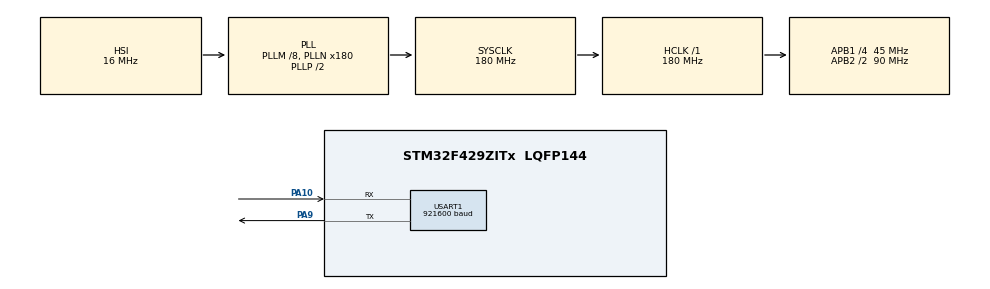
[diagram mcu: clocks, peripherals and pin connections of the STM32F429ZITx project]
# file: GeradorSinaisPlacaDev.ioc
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Mcu.Family=STM32F4
Mcu.Name=STM32F429ZITx
Mcu.Package=LQFP144
NVIC.PriorityGroup=NVIC_PRIORITYGROUP_4
NVIC.TIM7_IRQn=true\:0\:0\:false\:false\:true\:true\:true
NVIC.USART1_IRQn=true\:0\:0\:false\:false\:true\:true\:true
PA10.Mode=Asynchronous
PA10.Signal=USART1_RX
PA9.Mode=Asynchronous
PA9.Signal=USART1_TX
ProjectManager.HeapSize=0x200
ProjectManager.StackSize=0x400
ProjectManager.TargetToolchain=STM32CubeIDE
RCC.48MHZClocksFreq_Value=90000000
RCC.AHBFreq_Value=180000000
RCC.APB1CLKDivider=RCC_HCLK_DIV4
RCC.APB1Freq_Value=45000000
RCC.APB1TimFreq_Value=90000000
RCC.APB2CLKDivider=RCC_HCLK_DIV2
RCC.APB2Freq_Value=90000000
RCC.APB2TimFreq_Value=180000000
RCC.CortexFreq_Value=180000000
RCC.HCLKFreq_Value=180000000
RCC.HSE_VALUE=25000000
RCC.HSI_VALUE=16000000
RCC.LSE_VALUE=32768
RCC.PLLM=8
RCC.PLLN=180
RCC.SYSCLKFreq_VALUE=180000000
RCC.SYSCLKSource=RCC_SYSCLKSOURCE_PLLCLK
RCC.VCOOutputFreq_Value=360000000
TIM7.AutoReloadPreload=TIM_AUTORELOAD_PRELOAD_ENABLE
TIM7.Period=500
TIM7.Prescaler=90
TIM7.TIM_MasterOutputTrigger=TIM_TRGO_UPDATE
USART1.BaudRate=921600
USART1.VirtualMode=VM_ASYNC
VP_TIM7_VS_ClockSourceINT.Mode=Enable_Timer
board=custom

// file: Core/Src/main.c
/* USER CODE BEGIN Header */
/**
  ******************************************************************************
  * @file           : main.c
  * @brief          : Main program body
  ******************************************************************************
  * @attention
  *
  * <h2><center>&copy; Copyright (c) 2020 STMicroelectronics.
  * All rights reserved.</center></h2>
  *
  * This software component is licensed by ST under BSD 3-Clause license,
  * the "License"; You may not use this file except in compliance with the
  * License. You may obtain a copy of the License at:
  *                        opensource.org/licenses/BSD-3-Clause
  *
  ******************************************************************************
  */
/* USER CODE END Header */

#include "main.h"

/* USER CODE BEGIN Includes */

#include "Sinal.h"
#include <stdio.h>
/* USER CODE END Includes */

TIM_HandleTypeDef htim7;

UART_HandleTypeDef huart1;

/* USER CODE BEGIN PV */

volatile uint32_t TimeoutEnvioDados = 0;

/* USER CODE END PV */

void SystemClock_Config(void);
static void MX_GPIO_Init(void);
static void MX_USART1_UART_Init(void);
static void MX_TIM7_Init(void);

int main(void)
{

  /* MCU Configuration--------------------------------------------------------*/

  /* Reset of all peripherals, Initializes the Flash interface and the Systick. */
  HAL_Init();

  /* Configure the system clock */
  SystemClock_Config();

  /* Initialize all configured peripherals */
  MX_GPIO_Init();
  MX_USART1_UART_Init();
  MX_TIM7_Init();
  /* USER CODE BEGIN 2 */

  TimeoutEnvioDados = 1000;

  /* USER CODE END 2 */

  /* Infinite loop */
  while (1)
  {

    /* USER CODE BEGIN 3 */

	  if(TimeoutEnvioDados == 0){

//		  uint8_t pData[50] = " 0010 0020 0030\r";
//
//		  HAL_UART_Transmit_IT(&huart1, pData, 16);

		  TimeoutEnvioDados = 1;
	  }

  }
  /* USER CODE END 3 */
}

void SystemClock_Config(void)
{
  RCC_OscInitTypeDef RCC_OscInitStruct = {0};
  RCC_ClkInitTypeDef RCC_ClkInitStruct = {0};

  /** Configure the main internal regulator output voltage
  */
  __HAL_RCC_PWR_CLK_ENABLE();
  __HAL_PWR_VOLTAGESCALING_CONFIG(PWR_REGULATOR_VOLTAGE_SCALE1);
  /** Initializes the CPU, AHB and APB busses clocks
  */
  RCC_OscInitStruct.OscillatorType = RCC_OSCILLATORTYPE_HSI;
  RCC_OscInitStruct.HSIState = RCC_HSI_ON;
  RCC_OscInitStruct.HSICalibrationValue = RCC_HSICALIBRATION_DEFAULT;
  RCC_OscInitStruct.PLL.PLLState = RCC_PLL_ON;
  RCC_OscInitStruct.PLL.PLLSource = RCC_PLLSOURCE_HSI;
  RCC_OscInitStruct.PLL.PLLM = 8;
  RCC_OscInitStruct.PLL.PLLN = 180;
  RCC_OscInitStruct.PLL.PLLP = RCC_PLLP_DIV2;
  RCC_OscInitStruct.PLL.PLLQ = 4;
  if (HAL_RCC_OscConfig(&RCC_OscInitStruct) != HAL_OK)
  {
    Error_Handler();
  }
  /** Activate the Over-Drive mode
  */
  if (HAL_PWREx_EnableOverDrive() != HAL_OK)
  {
    Error_Handler();
  }
  /** Initializes the CPU, AHB and APB busses clocks
  */
  RCC_ClkInitStruct.ClockType = RCC_CLOCKTYPE_HCLK|RCC_CLOCKTYPE_SYSCLK
                              |RCC_CLOCKTYPE_PCLK1|RCC_CLOCKTYPE_PCLK2;
  RCC_ClkInitStruct.SYSCLKSource = RCC_SYSCLKSOURCE_PLLCLK;
  RCC_ClkInitStruct.AHBCLKDivider = RCC_SYSCLK_DIV1;
  RCC_ClkInitStruct.APB1CLKDivider = RCC_HCLK_DIV4;
  RCC_ClkInitStruct.APB2CLKDivider = RCC_HCLK_DIV2;

  if (HAL_RCC_ClockConfig(&RCC_ClkInitStruct, FLASH_LATENCY_5) != HAL_OK)
  {
    Error_Handler();
  }
}

static void MX_TIM7_Init(void)
{

  TIM_MasterConfigTypeDef sMasterConfig = {0};

  htim7.Instance = TIM7;
  htim7.Init.Prescaler = 90;
  htim7.Init.CounterMode = TIM_COUNTERMODE_UP;
  htim7.Init.Period = 500;
  htim7.Init.AutoReloadPreload = TIM_AUTORELOAD_PRELOAD_ENABLE;
  if (HAL_TIM_Base_Init(&htim7) != HAL_OK)
  {
    Error_Handler();
  }
  sMasterConfig.MasterOutputTrigger = TIM_TRGO_UPDATE;
  sMasterConfig.MasterSlaveMode = TIM_MASTERSLAVEMODE_DISABLE;
  if (HAL_TIMEx_MasterConfigSynchronization(&htim7, &sMasterConfig) != HAL_OK)
  {
    Error_Handler();
  }
  /* USER CODE BEGIN TIM7_Init 2 */

  __HAL_TIM_ENABLE(&htim7);
  __HAL_TIM_ENABLE_IT(&htim7,TIM_IT_UPDATE);

  /* USER CODE END TIM7_Init 2 */

}

static void MX_USART1_UART_Init(void)
{

  huart1.Instance = USART1;
  huart1.Init.BaudRate = 921600;
  huart1.Init.WordLength = UART_WORDLENGTH_8B;
  huart1.Init.StopBits = UART_STOPBITS_1;
  huart1.Init.Parity = UART_PARITY_NONE;
  huart1.Init.Mode = UART_MODE_TX_RX;
  huart1.Init.HwFlowCtl = UART_HWCONTROL_NONE;
  huart1.Init.OverSampling = UART_OVERSAMPLING_16;
  if (HAL_UART_Init(&huart1) != HAL_OK)
  {
    Error_Handler();
  }

}

static void MX_GPIO_Init(void)
{

  /* GPIO Ports Clock Enable */
  __HAL_RCC_GPIOA_CLK_ENABLE();

}

/* USER CODE BEGIN 4 */

/**
  * @brief  Period elapsed callback in non-blocking mode
  * @param  htim TIM handle
  * @retval None
  */
void HAL_TIM_PeriodElapsedCallback(TIM_HandleTypeDef *htim)
{
  /* Prevent unused argument(s) compilation warning */
//  UNUSED(htim);

	static uint32_t index = 0;

	if(index <= QtdAmostrasUtilizadas){

//		Sinal[index][0];
	  	 char pData[50] = " 0010 0020 0030\r";

	  	 int nbytes = sprintf(pData," %04u %04u %04u\r",(unsigned int)Sinal[index][0],(unsigned int)Sinal[index][1],(unsigned int)Sinal[index][2]);

		HAL_UART_Transmit_IT(&huart1, (uint8_t*)pData, nbytes);

		index++;
	}
}

/* USER CODE END 4 */

void Error_Handler(void)
{
}

/************************ (C) COPYRIGHT STMicroelectronics *****END OF FILE****/
